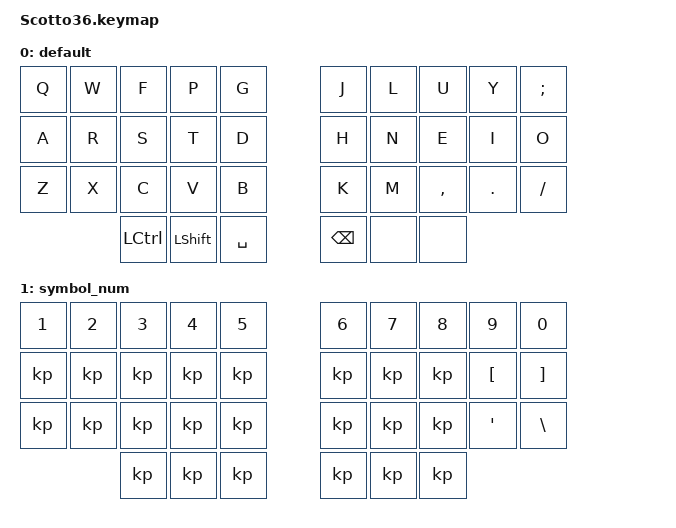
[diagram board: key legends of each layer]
#include <behaviors.dtsi>
#include <dt-bindings/zmk/keys.h>
#include "keys_it.h"

/ {
    keymap {
        compatible = "zmk,keymap";

        default {
            bindings = <
&kp Q  &kp W  &kp F      &kp P           &kp G      &kp J          &kp L  &kp U      &kp Y       &kp SEMICOLON
&kp A  &kp R  &kp S      &kp T           &kp D      &kp H          &kp N  &kp E      &kp I       &kp O
&kp Z  &kp X  &kp C      &kp V           &kp B      &kp K          &kp M  &kp COMMA  &kp PERIOD  &kp SLASH
              &kp LCTRL  &kp LEFT_SHIFT  &kp SPACE  &kp BACKSPACE  &none  &none
            >;
        };

        symbol_num {
            bindings = <
&kp NUMBER_1  &kp NUMBER_2  &kp NUMBER_3  &kp NUMBER_4  &kp N5  &kp NUMBER_6  &kp N7  &kp N8  &kp N9            &kp N0
&kp           &kp           &kp           &kp           &kp     &kp           &kp     &kp     &kp LEFT_BRACKET  &kp RIGHT_BRACKET
&kp           &kp           &kp           &kp           &kp     &kp           &kp     &kp     &kp SQT           &kp BACKSLASH
                            &kp           &kp           &kp     &kp           &kp     &kp
            >;
        };
    };
};
